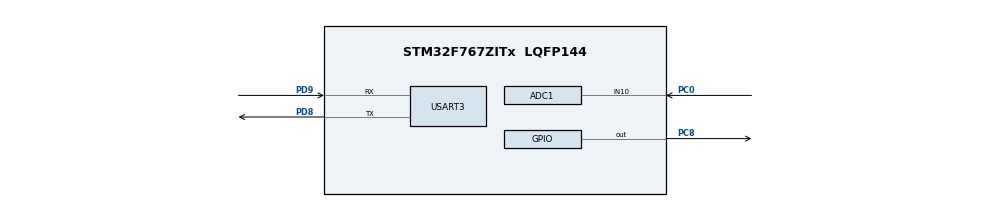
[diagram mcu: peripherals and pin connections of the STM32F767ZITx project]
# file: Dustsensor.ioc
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ADC1.Channel-0\#ChannelRegularConversion=ADC_CHANNEL_10
ADC1.ClockPrescaler=ADC_CLOCK_SYNC_PCLK_DIV4
ADC1.ContinuousConvMode=ENABLE
ADC1.EOCSelection=ADC_EOC_SEQ_CONV
ADC1.NbrOfConversionFlag=1
ADC1.Rank-0\#ChannelRegularConversion=1
ADC1.SamplingTime-0\#ChannelRegularConversion=ADC_SAMPLETIME_3CYCLES
ADC1.master=1
Mcu.Family=STM32F7
Mcu.Name=STM32F767ZITx
Mcu.Package=LQFP144
NVIC.PriorityGroup=NVIC_PRIORITYGROUP_4
PC0.Signal=ADCx_IN10
PC8.Signal=GPIO_Output
PD8.Mode=Asynchronous
PD8.Signal=USART3_TX
PD9.Mode=Asynchronous
PD9.Signal=USART3_RX
ProjectManager.HeapSize=0x200
ProjectManager.StackSize=0x400
ProjectManager.TargetToolchain=MDK-ARM V5
RCC.HSE_VALUE=25000000
RCC.HSI_VALUE=16000000
RCC.LSE_VALUE=32768
RCC.USBFreq_Value=96000000
RCC.VCOOutputFreq_Value=192000000
SH.ADCx_IN10.0=ADC1_IN10,IN10
USART3.VirtualMode-Asynchronous=VM_ASYNC
board=custom

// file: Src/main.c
/* USER CODE BEGIN Header */
/**
  ******************************************************************************
  * @file           : main.c
  * @brief          : Main program body
  ******************************************************************************
  * @attention
  *
  * <h2><center>&copy; Copyright (c) 2019 STMicroelectronics.
  * All rights reserved.</center></h2>
  *
  * This software component is licensed by ST under BSD 3-Clause license,
  * the "License"; You may not use this file except in compliance with the
  * License. You may obtain a copy of the License at:
  *                        opensource.org/licenses/BSD-3-Clause
  *
  ******************************************************************************
  */
/* USER CODE END Header */

#include "main.h"
#include "adc.h"
#include "usart.h"
#include "gpio.h"
#include "dwt_stm32_delay.h"
/* USER CODE BEGIN Includes */
#include "string.h"
#include "stdio.h"
/* USER CODE END Includes */

void SystemClock_Config(void);

int main(void)
{

  /* MCU Configuration--------------------------------------------------------*/

  /* Reset of all peripherals, Initializes the Flash interface and the Systick. */
  HAL_Init();

  /* Configure the system clock */
  SystemClock_Config();

  /* Initialize all configured peripherals */
  MX_GPIO_Init();
  MX_ADC1_Init();
  MX_USART3_UART_Init();
	DWT_Delay_Init();
  /* USER CODE BEGIN 2 */
uint32_t samplingTime = 280;
uint32_t deltaTime = 40;
uint32_t sleepTime = 9680;

int voMeasured = 0;
float calcVoltage = 0;
float dustDensity = 0;
int AQI = 0;
int Imax[4] = {25,50,100,200};
int Imin[4] = {0,26,51,101};
int Cmax[4] = {25,37,50,90};
int Cmin[4] = {0,26,38,51};
char Buffer[100],n;
  /* USER CODE END 2 */
	HAL_ADC_Start(&hadc1);
  /* Infinite loop */
  while (1)
  {
		HAL_GPIO_WritePin(GPIOC,GPIO_PIN_8,GPIO_PIN_RESET);
		DWT_Delay_us(samplingTime);

		while(HAL_ADC_PollForConversion(&hadc1,100)!= HAL_OK){}
		voMeasured = HAL_ADC_GetValue(&hadc1);

		n = sprintf(Buffer,"---------------------\n\r");
		n += sprintf(Buffer+n,"Measured: %d\n\r",voMeasured);
		DWT_Delay_us(deltaTime);
		HAL_GPIO_WritePin(GPIOC,GPIO_PIN_8,GPIO_PIN_SET);
		DWT_Delay_us(sleepTime);

		calcVoltage = voMeasured * (5.0/4096.0);
		dustDensity = ((0.17*calcVoltage) - 0.1)*100;

		if(dustDensity < 0){
			dustDensity = 0.0;
		}
		if(dustDensity<=25){
			AQI = (((Imax[0]-Imin[0])/(Cmax[0]-Cmin[0]))*(dustDensity-Cmin[0]))+Imin[0];
		}else if(dustDensity > 25 & dustDensity <=37){
			AQI = (((Imax[1]-Imin[1])/(Cmax[1]-Cmin[1]))*(dustDensity-Cmin[1]))+Imin[1];
		}else if(dustDensity > 37 & dustDensity <=50){
			AQI = (((Imax[2]-Imin[2])/(Cmax[2]-Cmin[2]))*(dustDensity-Cmin[2]))+Imin[2];
		}else if(dustDensity > 51 & dustDensity <= 90){
			AQI = (((Imax[3]-Imin[3])/(Cmax[3]-Cmin[3]))*(dustDensity-Cmin[3]))+Imin[3];
		}else{

		}
		n += sprintf(Buffer+n,"Voltage: %.2f\n\r",calcVoltage);
		n += sprintf(Buffer+n,"dustDensity: %.2f\n\r",dustDensity);
		n += sprintf(Buffer+n,"AQI: %d\n\r",AQI);

		while(__HAL_UART_GET_FLAG(&huart3,UART_FLAG_TC)==RESET){}
		HAL_UART_Transmit(&huart3,(uint8_t *)Buffer ,strlen(Buffer),400);
		HAL_Delay(5000);
  }
}

void SystemClock_Config(void)
{
  RCC_OscInitTypeDef RCC_OscInitStruct = {0};
  RCC_ClkInitTypeDef RCC_ClkInitStruct = {0};
  RCC_PeriphCLKInitTypeDef PeriphClkInitStruct = {0};

  /** Configure the main internal regulator output voltage
  */
  __HAL_RCC_PWR_CLK_ENABLE();
  __HAL_PWR_VOLTAGESCALING_CONFIG(PWR_REGULATOR_VOLTAGE_SCALE3);
  /** Initializes the CPU, AHB and APB busses clocks
  */
  RCC_OscInitStruct.OscillatorType = RCC_OSCILLATORTYPE_HSI;
  RCC_OscInitStruct.HSIState = RCC_HSI_ON;
  RCC_OscInitStruct.HSICalibrationValue = RCC_HSICALIBRATION_DEFAULT;
  RCC_OscInitStruct.PLL.PLLState = RCC_PLL_NONE;
  if (HAL_RCC_OscConfig(&RCC_OscInitStruct) != HAL_OK)
  {
    Error_Handler();
  }
  /** Initializes the CPU, AHB and APB busses clocks
  */
  RCC_ClkInitStruct.ClockType = RCC_CLOCKTYPE_HCLK|RCC_CLOCKTYPE_SYSCLK
                              |RCC_CLOCKTYPE_PCLK1|RCC_CLOCKTYPE_PCLK2;
  RCC_ClkInitStruct.SYSCLKSource = RCC_SYSCLKSOURCE_HSI;
  RCC_ClkInitStruct.AHBCLKDivider = RCC_SYSCLK_DIV1;
  RCC_ClkInitStruct.APB1CLKDivider = RCC_HCLK_DIV1;
  RCC_ClkInitStruct.APB2CLKDivider = RCC_HCLK_DIV1;

  if (HAL_RCC_ClockConfig(&RCC_ClkInitStruct, FLASH_LATENCY_0) != HAL_OK)
  {
    Error_Handler();
  }
  PeriphClkInitStruct.PeriphClockSelection = RCC_PERIPHCLK_USART3;
  PeriphClkInitStruct.Usart3ClockSelection = RCC_USART3CLKSOURCE_PCLK1;
  if (HAL_RCCEx_PeriphCLKConfig(&PeriphClkInitStruct) != HAL_OK)
  {
    Error_Handler();
  }
}

void Error_Handler(void)
{
}

/************************ (C) COPYRIGHT STMicroelectronics *****END OF FILE****/
